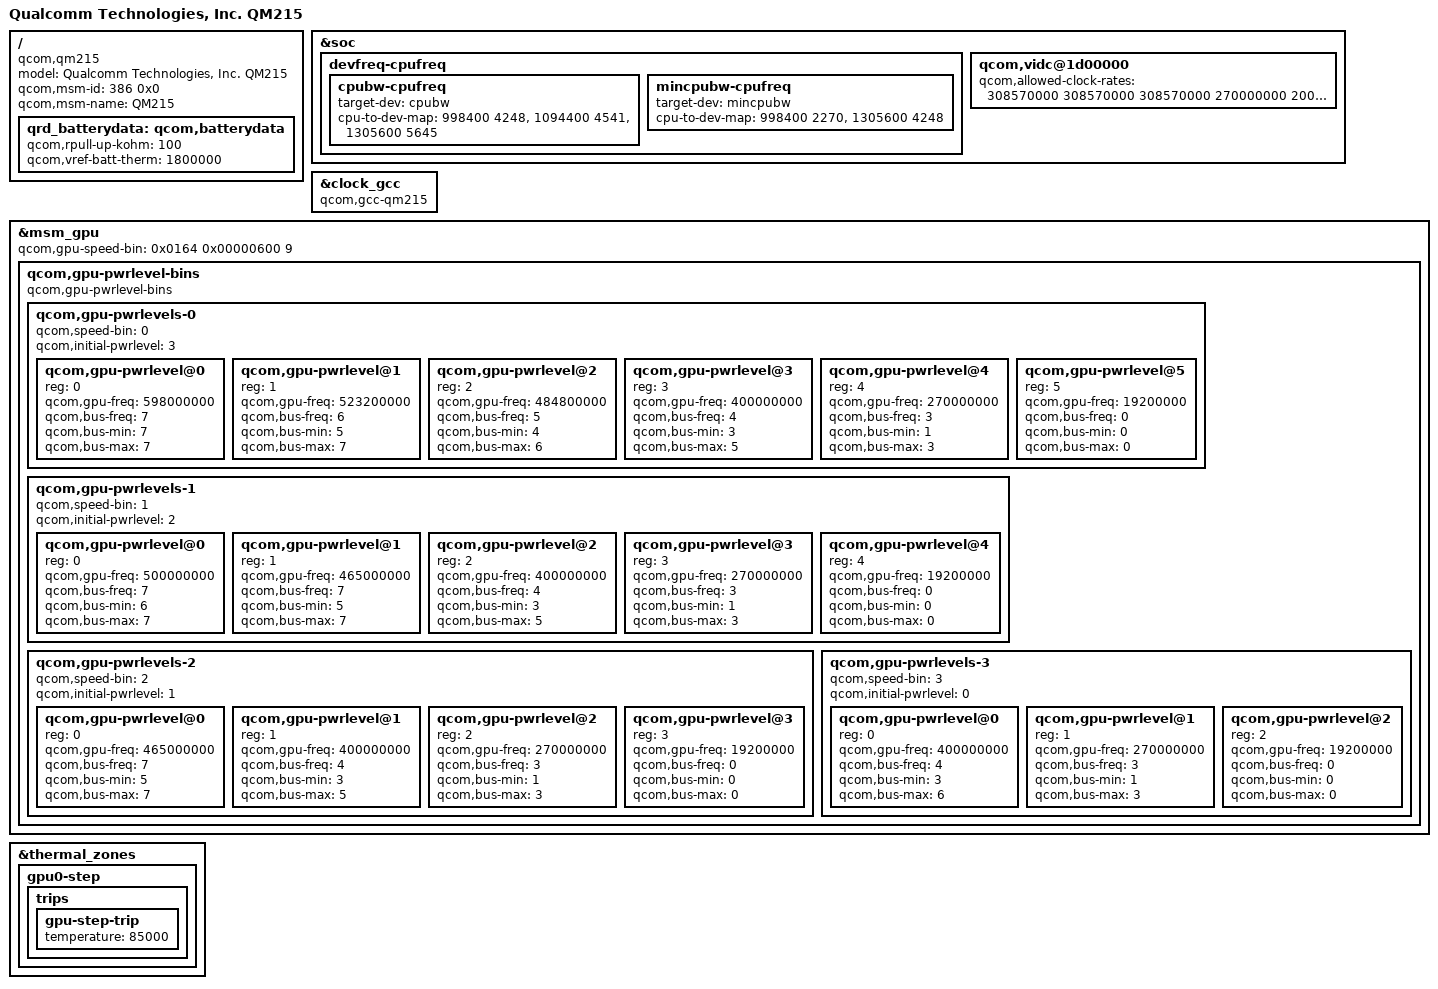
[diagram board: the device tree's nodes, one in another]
/*
 * Copyright (c) 2015-2019, The Linux Foundation. All rights reserved.
 *
 * This program is free software; you can redistribute it and/or modify
 * it under the terms of the GNU General Public License version 2 and
 * only version 2 as published by the Free Software Foundation.
 *
 * This program is distributed in the hope that it will be useful,
 * but WITHOUT ANY WARRANTY; without even the implied warranty of
 * MERCHANTABILITY or FITNESS FOR A PARTICULAR PURPOSE.  See the
 * GNU General Public License for more details.
 */

#include "msm8917.dtsi"
#include "qm215-camera.dtsi"
/ {
	model = "Qualcomm Technologies, Inc. QM215";
	compatible = "qcom,qm215";
	qcom,msm-id = <386 0x0>;
	qcom,msm-name = "QM215";
};

/ {
	qrd_batterydata: qcom,batterydata {
		qcom,rpull-up-kohm = <100>;
		qcom,vref-batt-therm = <1800000>;

		#include "vbms-batterydata-mlp356477-2800mah.dtsi"
	};
};

&soc {
	/delete-node/ devfreq-cpufreq;
	devfreq-cpufreq {
		cpubw-cpufreq {
		target-dev = <&cpubw>;
		cpu-to-dev-map =
			<  998400  4248 >,
			< 1094400  4541 >,
			< 1305600  5645 >;
		};

		mincpubw-cpufreq {
			target-dev = <&mincpubw>;
			cpu-to-dev-map =
				<  998400 2270 >,
				< 1305600 4248 >;
		};
	};
};

&soc {
	qcom,vidc@1d00000 {
		qcom,allowed-clock-rates = <308570000 308570000
					308570000 270000000 200000000>;
	};
};

&clock_gcc {
	compatible = "qcom,gcc-qm215";
};

/* GPU overrides */
&msm_gpu {

	qcom,gpu-speed-bin = <0x0164 0x00000600 9>;
	/delete-property/qcom,gpu-speed-bin-vectors;
	/delete-node/qcom,gpu-pwrlevel-bins;

	qcom,gpu-pwrlevel-bins {
		#address-cells = <1>;
		#size-cells = <0>;

		compatible="qcom,gpu-pwrlevel-bins";

		qcom,gpu-pwrlevels-0 {
			#address-cells = <1>;
			#size-cells = <0>;

			qcom,speed-bin = <0>;
			qcom,initial-pwrlevel = <3>;

			/* TURBO */
			qcom,gpu-pwrlevel@0 {
				reg = <0>;
				qcom,gpu-freq = <598000000>;
				qcom,bus-freq = <7>;
				qcom,bus-min = <7>;
				qcom,bus-max = <7>;
			};

			/* NOM+ */
			qcom,gpu-pwrlevel@1 {
				reg = <1>;
				qcom,gpu-freq = <523200000>;
				qcom,bus-freq = <6>;
				qcom,bus-min = <5>;
				qcom,bus-max = <7>;
			};

			/* NOM */
			qcom,gpu-pwrlevel@2 {
				reg = <2>;
				qcom,gpu-freq = <484800000>;
				qcom,bus-freq = <5>;
				qcom,bus-min = <4>;
				qcom,bus-max = <6>;
			};

			/* SVS+ */
			qcom,gpu-pwrlevel@3 {
				reg = <3>;
				qcom,gpu-freq = <400000000>;
				qcom,bus-freq = <4>;
				qcom,bus-min = <3>;
				qcom,bus-max = <5>;
			};

			/* SVS */
			qcom,gpu-pwrlevel@4 {
				reg = <4>;
				qcom,gpu-freq = <270000000>;
				qcom,bus-freq = <3>;
				qcom,bus-min = <1>;
				qcom,bus-max = <3>;
			};

			/* XO */
			qcom,gpu-pwrlevel@5 {
				reg = <5>;
				qcom,gpu-freq = <19200000>;
				qcom,bus-freq = <0>;
				qcom,bus-min = <0>;
				qcom,bus-max = <0>;
			};
		};

		qcom,gpu-pwrlevels-1 {
			#address-cells = <1>;
			#size-cells = <0>;

			qcom,speed-bin = <1>;
			qcom,initial-pwrlevel = <2>;

			/* NOM+ */
			qcom,gpu-pwrlevel@0 {
				reg = <0>;
				qcom,gpu-freq = <500000000>;
				qcom,bus-freq = <7>;
				qcom,bus-min = <6>;
				qcom,bus-max = <7>;
			};

			/* NOM */
			qcom,gpu-pwrlevel@1 {
				reg = <1>;
				qcom,gpu-freq = <465000000>;
				qcom,bus-freq = <7>;
				qcom,bus-min = <5>;
				qcom,bus-max = <7>;
			};

			/* SVS+ */
			qcom,gpu-pwrlevel@2 {
				reg = <2>;
				qcom,gpu-freq = <400000000>;
				qcom,bus-freq = <4>;
				qcom,bus-min = <3>;
				qcom,bus-max = <5>;
			};

			/* SVS */
			qcom,gpu-pwrlevel@3 {
				reg = <3>;
				qcom,gpu-freq = <270000000>;
				qcom,bus-freq = <3>;
				qcom,bus-min = <1>;
				qcom,bus-max = <3>;
			};

			/* XO */
			qcom,gpu-pwrlevel@4 {
				reg = <4>;
				qcom,gpu-freq = <19200000>;
				qcom,bus-freq = <0>;
				qcom,bus-min = <0>;
				qcom,bus-max = <0>;
			};
		};

		qcom,gpu-pwrlevels-2 {
			#address-cells = <1>;
			#size-cells = <0>;

			qcom,speed-bin = <2>;
			qcom,initial-pwrlevel = <1>;

			/* NOM */
			qcom,gpu-pwrlevel@0 {
				reg = <0>;
				qcom,gpu-freq = <465000000>;
				qcom,bus-freq = <7>;
				qcom,bus-min = <5>;
				qcom,bus-max = <7>;
			};

			/* SVS+ */
			qcom,gpu-pwrlevel@1 {
				reg = <1>;
				qcom,gpu-freq = <400000000>;
				qcom,bus-freq = <4>;
				qcom,bus-min = <3>;
				qcom,bus-max = <5>;
			};

			/* SVS */
			qcom,gpu-pwrlevel@2 {
				reg = <2>;
				qcom,gpu-freq = <270000000>;
				qcom,bus-freq = <3>;
				qcom,bus-min = <1>;
				qcom,bus-max = <3>;
			};

			/* XO */
			qcom,gpu-pwrlevel@3 {
				reg = <3>;
				qcom,gpu-freq = <19200000>;
				qcom,bus-freq = <0>;
				qcom,bus-min = <0>;
				qcom,bus-max = <0>;
			};
		};

		qcom,gpu-pwrlevels-3 {
			#address-cells = <1>;
			#size-cells = <0>;

			qcom,speed-bin = <3>;
			qcom,initial-pwrlevel = <0>;

			/* SVS+ */
			qcom,gpu-pwrlevel@0 {
				reg = <0>;
				qcom,gpu-freq = <400000000>;
				qcom,bus-freq = <4>;
				qcom,bus-min = <3>;
				qcom,bus-max = <6>;
			};

			/* SVS */
			qcom,gpu-pwrlevel@1 {
				reg = <1>;
				qcom,gpu-freq = <270000000>;
				qcom,bus-freq = <3>;
				qcom,bus-min = <1>;
				qcom,bus-max = <3>;
			};

			/* XO */
			qcom,gpu-pwrlevel@2 {
				reg = <2>;
				qcom,gpu-freq = <19200000>;
				qcom,bus-freq = <0>;
				qcom,bus-min = <0>;
				qcom,bus-max = <0>;
			};
		};
	};
};

&thermal_zones {
	gpu0-step {
		trips {
			gpu-step-trip {
				temperature = <85000>;
			};
		};
	};
};
